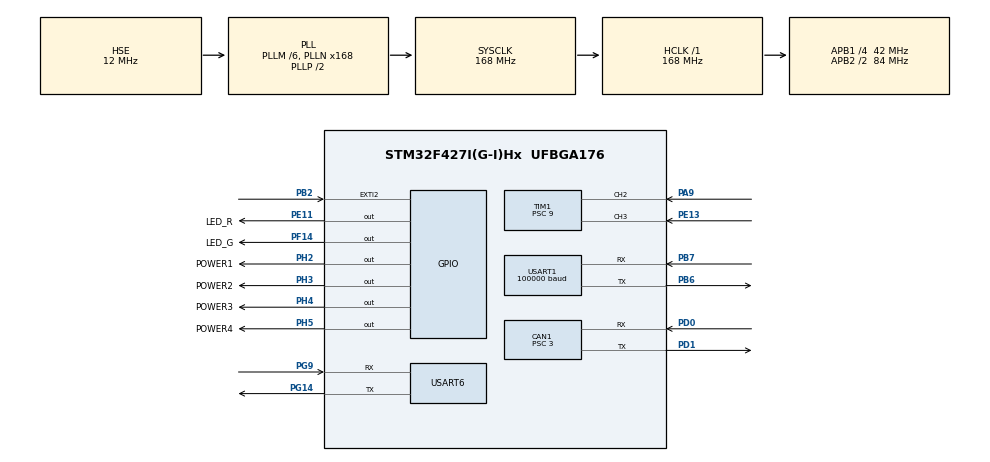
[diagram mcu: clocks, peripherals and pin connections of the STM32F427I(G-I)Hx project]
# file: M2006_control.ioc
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CAN1.ABOM=ENABLE
CAN1.BS1=CAN_BS1_9TQ
CAN1.BS2=CAN_BS2_4TQ
CAN1.CalculateBaudRate=1000000
CAN1.CalculateTimeBit=1000
CAN1.CalculateTimeQuantum=71.42857142857143
CAN1.Prescaler=3
CAN1.SJW=CAN_SJW_1TQ
Dma.Request0=TIM1_CH1/CH2/CH3
Dma.Request1=USART1_RX
Dma.TIM1_CH1/CH2/CH3.0.Direction=DMA_PERIPH_TO_MEMORY
Dma.TIM1_CH1/CH2/CH3.0.FIFOMode=DMA_FIFOMODE_DISABLE
Dma.TIM1_CH1/CH2/CH3.0.Instance=DMA2_Stream6
Dma.TIM1_CH1/CH2/CH3.0.MemDataAlignment=DMA_MDATAALIGN_HALFWORD
Dma.TIM1_CH1/CH2/CH3.0.MemInc=DMA_MINC_ENABLE
Dma.TIM1_CH1/CH2/CH3.0.Mode=DMA_CIRCULAR
Dma.TIM1_CH1/CH2/CH3.0.PeriphDataAlignment=DMA_PDATAALIGN_HALFWORD
Dma.TIM1_CH1/CH2/CH3.0.PeriphInc=DMA_PINC_DISABLE
Dma.TIM1_CH1/CH2/CH3.0.Priority=DMA_PRIORITY_LOW
Dma.USART1_RX.1.Direction=DMA_PERIPH_TO_MEMORY
Dma.USART1_RX.1.FIFOMode=DMA_FIFOMODE_DISABLE
Dma.USART1_RX.1.Instance=DMA2_Stream2
Dma.USART1_RX.1.MemDataAlignment=DMA_MDATAALIGN_BYTE
Dma.USART1_RX.1.MemInc=DMA_MINC_ENABLE
Dma.USART1_RX.1.Mode=DMA_NORMAL
Dma.USART1_RX.1.PeriphDataAlignment=DMA_PDATAALIGN_BYTE
Dma.USART1_RX.1.PeriphInc=DMA_PINC_DISABLE
Dma.USART1_RX.1.Priority=DMA_PRIORITY_LOW
Mcu.Family=STM32F4
Mcu.Name=STM32F427I(G-I)Hx
Mcu.Package=UFBGA176
NVIC.CAN1_RX0_IRQn=true\:0\:0\:false\:false\:true\:true\:true\:true
NVIC.CAN1_TX_IRQn=true\:0\:0\:false\:false\:true\:true\:true\:true
NVIC.DMA2_Stream2_IRQn=true\:0\:0\:false\:false\:true\:false\:true\:true
NVIC.DMA2_Stream6_IRQn=true\:0\:0\:false\:false\:true\:false\:true\:true
NVIC.EXTI2_IRQn=true\:0\:0\:false\:false\:true\:true\:true\:true
NVIC.PriorityGroup=NVIC_PRIORITYGROUP_4
NVIC.TIM6_DAC_IRQn=true\:15\:0\:false\:false\:true\:false\:true\:true
NVIC.TimeBase=TIM6_DAC_IRQn
NVIC.TimeBaseIP=TIM6
NVIC.USART1_IRQn=true\:0\:0\:false\:false\:true\:true\:true\:true
NVIC.USART6_IRQn=true\:0\:0\:false\:false\:true\:true\:true\:true
PA13.Mode=Serial_Wire
PA13.Signal=SYS_JTMS-SWDIO
PA14.Mode=Serial_Wire
PA14.Signal=SYS_JTCK-SWCLK
PA9.Signal=S_TIM1_CH2
PB2/BOOT1.GPIO_ModeDefaultEXTI=GPIO_MODE_IT_FALLING
PB2/BOOT1.GPIO_PuPd=GPIO_PULLUP
PB2/BOOT1.Signal=GPXTI2
PB6.Mode=Asynchronous
PB6.Signal=USART1_TX
PB7.Mode=Asynchronous
PB7.Signal=USART1_RX
PD0.Mode=CAN_Activate
PD0.Signal=CAN1_RX
PD1.Mode=CAN_Activate
PD1.Signal=CAN1_TX
PE11.GPIO_Label=LED_R
PE11.PinState=GPIO_PIN_RESET
PE11.Signal=GPIO_Output
PE13.Signal=S_TIM1_CH3
PF14.GPIO_Label=LED_G
PF14.PinState=GPIO_PIN_RESET
PF14.Signal=GPIO_Output
PG14.Mode=Asynchronous
PG14.Signal=USART6_TX
PG9.Mode=Asynchronous
PG9.Signal=USART6_RX
PH0/OSC_IN.Mode=HSE-External-Oscillator
PH0/OSC_IN.Signal=RCC_OSC_IN
PH1/OSC_OUT.Mode=HSE-External-Oscillator
PH1/OSC_OUT.Signal=RCC_OSC_OUT
PH2.GPIO_Label=POWER1
PH2.Signal=GPIO_Output
PH3.GPIO_Label=POWER2
PH3.Signal=GPIO_Output
PH4.GPIO_Label=POWER3
PH4.Signal=GPIO_Output
PH5.GPIO_Label=POWER4
PH5.Signal=GPIO_Output
ProjectManager.HeapSize=0x200
ProjectManager.StackSize=0x400
ProjectManager.TargetToolchain=MDK-ARM V5
RCC.48MHZClocksFreq_Value=84000000
RCC.AHBFreq_Value=168000000
RCC.APB1CLKDivider=RCC_HCLK_DIV4
RCC.APB1Freq_Value=42000000
RCC.APB1TimFreq_Value=84000000
RCC.APB2CLKDivider=RCC_HCLK_DIV2
RCC.APB2Freq_Value=84000000
RCC.APB2TimFreq_Value=168000000
RCC.CortexFreq_Value=168000000
RCC.HCLKFreq_Value=168000000
RCC.HSE_VALUE=12000000
RCC.HSI_VALUE=16000000
RCC.LSE_VALUE=32768
RCC.PLLM=6
RCC.PLLN=168
RCC.PLLSourceVirtual=RCC_PLLSOURCE_HSE
RCC.SYSCLKFreq_VALUE=168000000
RCC.SYSCLKSource=RCC_SYSCLKSOURCE_PLLCLK
RCC.VCOOutputFreq_Value=336000000
SH.S_TIM1_CH2.0=TIM1_CH2,Input_Capture2_from_TI2
SH.S_TIM1_CH2.1=TIM1_CH2,Input_Capture1_from_TI2
SH.S_TIM1_CH3.0=TIM1_CH3,Input_Capture3_from_TI3
SH.S_TIM1_CH3.1=TIM1_CH3,Input_Capture4_from_TI3
TIM1.Channel-Input_Capture1_from_TI2=TIM_CHANNEL_1
TIM1.Channel-Input_Capture2_from_TI2=TIM_CHANNEL_2
TIM1.Channel-Input_Capture3_from_TI3=TIM_CHANNEL_3
TIM1.Channel-Input_Capture4_from_TI3=TIM_CHANNEL_4
TIM1.Period=9999
TIM1.Prescaler=9
USART1.BaudRate=100000
USART1.Parity=PARITY_EVEN
USART1.VirtualMode=VM_ASYNC
USART6.VirtualMode=VM_ASYNC
VP_SYS_VS_tim6.Mode=TIM6
board=custom

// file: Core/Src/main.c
/* USER CODE BEGIN Header */
/**
  ******************************************************************************
  * @file           : main.c
  * @brief          : Main program body
  ******************************************************************************
  * @attention
  *
  * Copyright (c) 2023 STMicroelectronics.
  * All rights reserved.
  *
  * This software is licensed under terms that can be found in the LICENSE file
  * in the root directory of this software component.
  * If no LICENSE file comes with this software, it is provided AS-IS.
  *
  ******************************************************************************
  */
/* USER CODE END Header */
#include "main.h"
#include "can.h"
#include "dma.h"
#include "tim.h"
#include "usart.h"
#include "gpio.h"

/* USER CODE BEGIN Includes */
#include "bsp_can.h"
#include "pid.h"
#define num 1
/* USER CODE END Includes */

void SystemClock_Config(void);

int main(void)
{
  /* USER CODE BEGIN 1 */
	int spd_set=0;
	int spd_target=0;
  /* USER CODE END 1 */

  /* MCU Configuration--------------------------------------------------------*/

  /* Reset of all peripherals, Initializes the Flash interface and the Systick. */
  HAL_Init();

  /* Configure the system clock */
  SystemClock_Config();

  /* Initialize all configured peripherals */
  MX_GPIO_Init();
  MX_DMA_Init();
  MX_CAN1_Init();
  MX_USART6_UART_Init();
  MX_TIM1_Init();
  MX_USART1_UART_Init();
  /* USER CODE BEGIN 2 */
	HAL_GPIO_WritePin(GPIOH,GPIO_PIN_2,GPIO_PIN_SET);
	HAL_GPIO_WritePin(GPIOH,GPIO_PIN_3,GPIO_PIN_SET);
	HAL_GPIO_WritePin(GPIOH,GPIO_PIN_4,GPIO_PIN_SET);
	HAL_GPIO_WritePin(GPIOH,GPIO_PIN_5,GPIO_PIN_SET);
	HAL_Delay(10);

  /* USER CODE END 2 */

  /* Infinite loop */
  /* USER CODE BEGIN WHILE */
	pid_init(&motor_pid[0]);
	motor_pid[0].f_param_init(&motor_pid[0],PID_Speed,16384,5000,10,0,8000,0,1.5,0.1,0);
	set_moto_current(&hcan1,0,0,0,0 );
	printf("初始化结束。\r\n");
  while (1)
  {
    /* USER CODE END WHILE */

  }
}

void SystemClock_Config(void)
{
  RCC_OscInitTypeDef RCC_OscInitStruct = {0};
  RCC_ClkInitTypeDef RCC_ClkInitStruct = {0};

  /** Configure the main internal regulator output voltage
  */
  __HAL_RCC_PWR_CLK_ENABLE();
  __HAL_PWR_VOLTAGESCALING_CONFIG(PWR_REGULATOR_VOLTAGE_SCALE1);

  /** Initializes the RCC Oscillators according to the specified parameters
  * in the RCC_OscInitTypeDef structure.
  */
  RCC_OscInitStruct.OscillatorType = RCC_OSCILLATORTYPE_HSE;
  RCC_OscInitStruct.HSEState = RCC_HSE_ON;
  RCC_OscInitStruct.PLL.PLLState = RCC_PLL_ON;
  RCC_OscInitStruct.PLL.PLLSource = RCC_PLLSOURCE_HSE;
  RCC_OscInitStruct.PLL.PLLM = 6;
  RCC_OscInitStruct.PLL.PLLN = 168;
  RCC_OscInitStruct.PLL.PLLP = RCC_PLLP_DIV2;
  RCC_OscInitStruct.PLL.PLLQ = 4;
  if (HAL_RCC_OscConfig(&RCC_OscInitStruct) != HAL_OK)
  {
    Error_Handler();
  }

  /** Initializes the CPU, AHB and APB buses clocks
  */
  RCC_ClkInitStruct.ClockType = RCC_CLOCKTYPE_HCLK|RCC_CLOCKTYPE_SYSCLK
                              |RCC_CLOCKTYPE_PCLK1|RCC_CLOCKTYPE_PCLK2;
  RCC_ClkInitStruct.SYSCLKSource = RCC_SYSCLKSOURCE_PLLCLK;
  RCC_ClkInitStruct.AHBCLKDivider = RCC_SYSCLK_DIV1;
  RCC_ClkInitStruct.APB1CLKDivider = RCC_HCLK_DIV4;
  RCC_ClkInitStruct.APB2CLKDivider = RCC_HCLK_DIV2;

  if (HAL_RCC_ClockConfig(&RCC_ClkInitStruct, FLASH_LATENCY_5) != HAL_OK)
  {
    Error_Handler();
  }
}

void HAL_TIM_PeriodElapsedCallback(TIM_HandleTypeDef *htim)
{
  if (htim->Instance == TIM6) {
    HAL_IncTick();
  }
}

void Error_Handler(void)
{
  __disable_irq();
  while (1)
  {
  }
}
